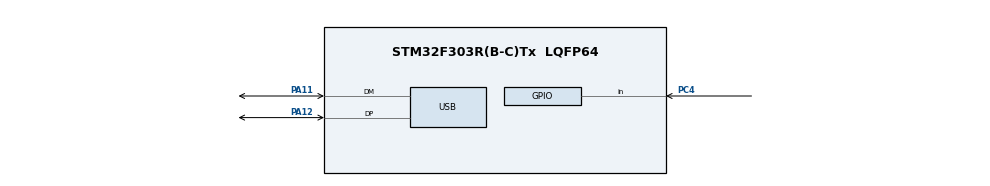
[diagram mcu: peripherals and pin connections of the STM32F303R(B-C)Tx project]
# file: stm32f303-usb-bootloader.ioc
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Mcu.Family=STM32F3
USB_DEVICE.CLASS_NAME_FS=MSC
RCC.CortexFreq_Value=72000000
USB_DEVICE.VirtualModeFS=Msc_FS
PC4.GPIO_PuPd=GPIO_PULLUP
NVIC.USB_LP_CAN_RX0_IRQn=true\:0\:0\:false\:false\:true\:false\:true
RCC.SYSCLKSourceVirtual=RCC_SYSCLKSOURCE_PLLCLK
PC4.Signal=GPIO_Input
PA11.Mode=Device
RCC.APB1CLKDivider=RCC_HCLK_DIV2
ProjectManager.StackSize=0x400
PA13.Signal=SYS_JTMS-SWDIO
USB_DEVICE.MANUFACTURER_STRING=SxLab
PA12.Signal=USB_DP
ProjectManager.TargetToolchain=STM32CubeIDE
RCC.HCLKFreq_Value=72000000
RCC.APB2TimFreq_Value=72000000
RCC.USBFreq_Value=48000000
RCC.LSE_VALUE=32768
RCC.AHBFreq_Value=72000000
PF0-OSC_IN.Mode=HSE-External-Oscillator
RCC.HSE_VALUE=8000000
board=custom
RCC.PLLMUL=RCC_PLL_MUL9
RCC.APB2Freq_Value=72000000
RCC.PRESCALERUSB=RCC_USBCLKSOURCE_PLL_DIV1_5
USB_DEVICE.PRODUCT_STRING_MSC_FS=Fortress bootloader
PA14.Mode=Serial_Wire
PA13.Mode=Serial_Wire
Mcu.Name=STM32F303R(B-C)Tx
RCC.SYSCLKFreq_VALUE=72000000
Mcu.Package=LQFP64
PA12.Mode=Device
PA11.Signal=USB_DM
PA14.Signal=SYS_JTCK-SWCLK
ProjectManager.HeapSize=0x200
RCC.HSI_VALUE=8000000
NVIC.PriorityGroup=NVIC_PRIORITYGROUP_4
RCC.APB1TimFreq_Value=72000000
VP_USB_DEVICE_VS_USB_DEVICE_MSC_FS.Mode=MSC_FS
PF0-OSC_IN.Signal=RCC_OSC_IN
PF1-OSC_OUT.Mode=HSE-External-Oscillator
RCC.APB1Freq_Value=36000000
USB_DEVICE.VirtualMode=Msc
PF1-OSC_OUT.Signal=RCC_OSC_OUT

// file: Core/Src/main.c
/* USER CODE BEGIN Header */
/**
  ******************************************************************************
  * @file           : main.c
  * @brief          : Main program body
  ******************************************************************************
  * @attention
  *
  * <h2><center>&copy; Copyright (c) 2024 STMicroelectronics.
  * All rights reserved.</center></h2>
  *
  * This software component is licensed by ST under BSD 3-Clause license,
  * the "License"; You may not use this file except in compliance with the
  * License. You may obtain a copy of the License at:
  *                        opensource.org/licenses/BSD-3-Clause
  *
  ******************************************************************************
  */
/* USER CODE END Header */
#include "main.h"
#include "usb_device.h"

/* USER CODE BEGIN Includes */
#include <stdint.h>
#include <stdbool.h>
#include "main.h"
#include "usb_device.h"
#include "btldr_config.h"
#include "ihex_parser.h"
#include "drv/led.h"
/* USER CODE END Includes */

void SystemClock_Config(void);
static void MX_GPIO_Init(void);
/* USER CODE BEGIN PFP */
extern PCD_HandleTypeDef hpcd_USB_FS;

/* USER CODE END PFP */

/* USER CODE BEGIN 0 */

bool is_button_down(void)
{
    return (!LL_GPIO_IsInputPinSet(GPIOC, LL_GPIO_PIN_4));
}

bool is_appcode_exist(void)
{
  uint32_t *mem = (uint32_t*)APP_ADDR;

  if ((mem[0] == 0x00000000 || mem[0] == 0xFFFFFFFF) && \
      (mem[1] == 0x00000000 || mem[1] == 0xFFFFFFFF) && \
      (mem[2] == 0x00000000 || mem[2] == 0xFFFFFFFF) && \
      (mem[3] == 0x00000000 || mem[3] == 0xFFFFFFFF))
  {
    return false;
  }
  else
  {
    return true;
  }
}

void SystemReset(void){
    LL_mDelay(500);

    HAL_PCD_Stop(&hpcd_USB_FS);

    /* Pull USB D+ PIN to GND so USB Host detects device disconnect */
    LL_GPIO_SetPinMode(GPIOA,LL_GPIO_PIN_12, LL_GPIO_MODE_OUTPUT);
    LL_GPIO_SetPinSpeed(GPIOA, LL_GPIO_PIN_12, LL_GPIO_SPEED_FREQ_LOW);
    LL_GPIO_SetPinOutputType(GPIOA,LL_GPIO_PIN_12, LL_GPIO_OUTPUT_PUSHPULL);
    LL_GPIO_ResetOutputPin(GPIOA, LL_GPIO_PIN_12);

    LL_mDelay(1000);

    NVIC_SystemReset();
}

/* USER CODE END 0 */

int main(void)
{

	static uint32_t jump_addr;
	//

	MX_GPIO_Init();
	for(uint32_t i = 0; i < 10000; i++) {
		__asm("nop");
	}

  if(is_button_down()) {
	  SystemClock_Config();
	  HAL_Init();
	  MX_USB_DEVICE_Init();
	  LL_mDelay(10);
	  led_init();

		uint32_t t = 0;

	  while(1) {
		for(uint8_t i = 0; i < LED_NUMBER; i++) {
			uint16_t br = 15 - ((((t >> 1) + i * 44) & 0x3FF) >> 7);
			if (br > 10) {br -= 10;}
			else {br = 0;}
			br <<= 1;
			led_set(i, 0xFFFFFF, br);
		}

		  led_update();

		  t++;

	      if(ihex_is_eof()) {
	         SystemReset();
	      }
	  }
  } else {

		jump_addr = *((__IO uint32_t*)(APP_ADDR+4u));
		HAL_DeInit();
		// Disable all interrupts
		NVIC->ICER[0] = 0xFFFFFFFF;
		NVIC->ICER[1] = 0xFFFFFFFF;
		NVIC->ICER[2] = 0xFFFFFFFF;
		NVIC->ICER[3] = 0xFFFFFFFF;
		NVIC->ICER[4] = 0xFFFFFFFF;
		NVIC->ICER[5] = 0xFFFFFFFF;
		NVIC->ICER[6] = 0xFFFFFFFF;
		NVIC->ICER[7] = 0xFFFFFFFF;

		NVIC->ICPR[0] = 0xFFFFFFFF;
		NVIC->ICPR[1] = 0xFFFFFFFF;
		NVIC->ICPR[2] = 0xFFFFFFFF;
		NVIC->ICPR[3] = 0xFFFFFFFF;
		NVIC->ICPR[4] = 0xFFFFFFFF;
		NVIC->ICPR[5] = 0xFFFFFFFF;
		NVIC->ICPR[6] = 0xFFFFFFFF;
		NVIC->ICPR[7] = 0xFFFFFFFF;

		/* deactivate SysTick */
		SysTick->CTRL = 0;

		/* Change the main stack pointer. */
		SCB->VTOR = APP_ADDR;
		__set_MSP((*(__IO uint32_t*)APP_ADDR));
		__DSB();
		((void (*) (void)) (jump_addr)) ();

  }

  while (1)
  {

  }

}

void SystemClock_Config(void)
{
  LL_FLASH_SetLatency(LL_FLASH_LATENCY_2);
  while(LL_FLASH_GetLatency()!= LL_FLASH_LATENCY_2)
  {
  }
  LL_RCC_HSE_Enable();

   /* Wait till HSE is ready */
  while(LL_RCC_HSE_IsReady() != 1)
  {

  }
  LL_RCC_PLL_ConfigDomain_SYS(LL_RCC_PLLSOURCE_HSE_DIV_1, LL_RCC_PLL_MUL_9);
  LL_RCC_PLL_Enable();

   /* Wait till PLL is ready */
  while(LL_RCC_PLL_IsReady() != 1)
  {

  }
  LL_RCC_SetAHBPrescaler(LL_RCC_SYSCLK_DIV_1);
  LL_RCC_SetAPB1Prescaler(LL_RCC_APB1_DIV_2);
  LL_RCC_SetAPB2Prescaler(LL_RCC_APB1_DIV_1);
  LL_RCC_SetSysClkSource(LL_RCC_SYS_CLKSOURCE_PLL);

   /* Wait till System clock is ready */
  while(LL_RCC_GetSysClkSource() != LL_RCC_SYS_CLKSOURCE_STATUS_PLL)
  {

  }
  LL_SetSystemCoreClock(72000000);

   /* Update the time base */
  if (HAL_InitTick (TICK_INT_PRIORITY) != HAL_OK)
  {
    Error_Handler();
  }
  LL_RCC_SetUSBClockSource(LL_RCC_USB_CLKSOURCE_PLL_DIV_1_5);
}

static void MX_GPIO_Init(void)
{
  LL_GPIO_InitTypeDef GPIO_InitStruct = {0};

  /* GPIO Ports Clock Enable */
  LL_AHB1_GRP1_EnableClock(LL_AHB1_GRP1_PERIPH_GPIOF);
  LL_AHB1_GRP1_EnableClock(LL_AHB1_GRP1_PERIPH_GPIOC);
  LL_AHB1_GRP1_EnableClock(LL_AHB1_GRP1_PERIPH_GPIOA);

  /**/
  GPIO_InitStruct.Pin = LL_GPIO_PIN_4;
  GPIO_InitStruct.Mode = LL_GPIO_MODE_INPUT;
  GPIO_InitStruct.Pull = LL_GPIO_PULL_UP;
  LL_GPIO_Init(GPIOC, &GPIO_InitStruct);

}

void Error_Handler(void)
{
  __disable_irq();
  while (1)
  {
  }
}

/************************ (C) COPYRIGHT STMicroelectronics *****END OF FILE****/
